# ATmega1609 register map
Vendor: Atmel; File version: 1.0
CPU: other r0p0, little endian, no MPU, no FPU, 4 interrupt priority bits
Registers are 8-bit, read-write, reset 0x0 unless marked. A register's access mark holds for its fields unless they carry their own. Offsets are from the block's base; [hi:lo] are bit positions; {n}, {i} and the like mark numbered series.

## PORTA — I/O Ports
Base 0x00000400
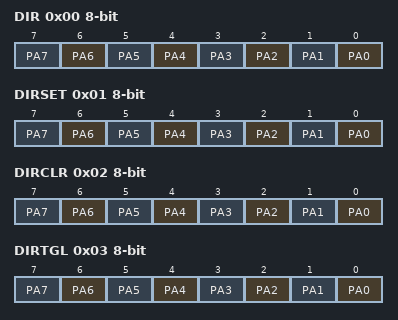
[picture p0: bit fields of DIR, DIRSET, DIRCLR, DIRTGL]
0x00 DIR — Data Direction
  [n] PA{n} (n=0..7) — Pin A{n}
0x01 DIRSET — Data Direction Set
  [n] PA{n} (n=0..7) — Pin A{n}
0x02 DIRCLR — Data Direction Clear
  [n] PA{n} (n=0..7) — Pin A{n}
0x03 DIRTGL — Data Direction Toggle
  [n] PA{n} (n=0..7) — Pin A{n}
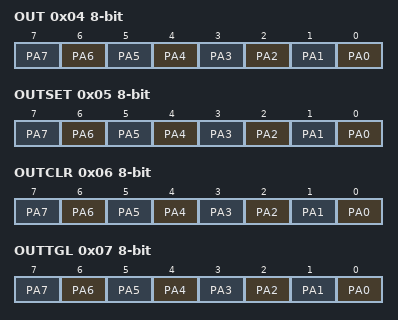
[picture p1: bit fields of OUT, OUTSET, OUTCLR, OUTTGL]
0x04 OUT — Output Value
  [n] PA{n} (n=0..7) — Pin A{n}
0x05 OUTSET — Output Value Set
  [n] PA{n} (n=0..7) — Pin A{n}
0x06 OUTCLR — Output Value Clear
  [n] PA{n} (n=0..7) — Pin A{n}
0x07 OUTTGL — Output Value Toggle
  [n] PA{n} (n=0..7) — Pin A{n}
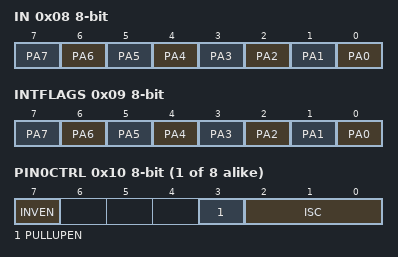
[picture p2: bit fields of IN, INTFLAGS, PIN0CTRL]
0x08 IN — Input Value
  [n] PA{n} (n=0..7) — Pin A{n}
0x09 INTFLAGS — Interrupt Flags
  [n] PA{n} (n=0..7) — Pin A{n}
0x0A PORTCTRL — Port Control
  [0] SRL — Slew Rate Limit Enable
{0x10+i} PIN{i}CTRL (i=0..7) — Pin {i} Control
  [7] INVEN — Inverted I/O Enable
  [3] PULLUPEN — Pullup enable
  [2:0] ISC — Input/Sense Configuration
    0=INTDISABLE (Interrupt disabled but input buffer enabled); 1=BOTHEDGES (Sense Both Edges); 2=RISING (Sense Rising Edge); 3=FALLING (Sense Falling Edge); 4=INPUT_DISABLE (Digital Input Buffer disabled); 5=LEVEL (Sense low Level)

## PORTB — I/O Ports
Base 0x00000420
Registers as PORTA; these are added or differ:
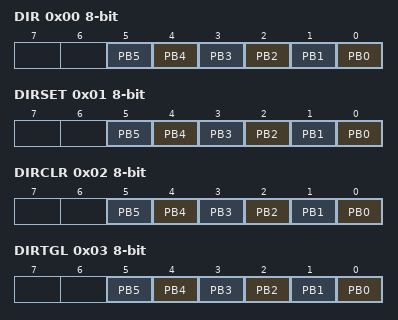
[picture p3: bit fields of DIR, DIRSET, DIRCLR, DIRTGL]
0x00 DIR — Data Direction
  [n] PB{n} (n=0..5) — Pin B{n}
0x01 DIRSET — Data Direction Set
  [n] PB{n} (n=0..5) — Pin B{n}
0x02 DIRCLR — Data Direction Clear
  [n] PB{n} (n=0..5) — Pin B{n}
0x03 DIRTGL — Data Direction Toggle
  [n] PB{n} (n=0..5) — Pin B{n}
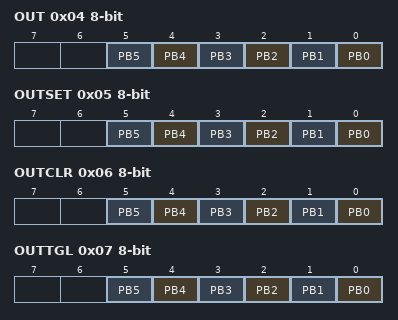
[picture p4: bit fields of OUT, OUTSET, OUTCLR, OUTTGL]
0x04 OUT — Output Value
  [n] PB{n} (n=0..5) — Pin B{n}
0x05 OUTSET — Output Value Set
  [n] PB{n} (n=0..5) — Pin B{n}
0x06 OUTCLR — Output Value Clear
  [n] PB{n} (n=0..5) — Pin B{n}
0x07 OUTTGL — Output Value Toggle
  [n] PB{n} (n=0..5) — Pin B{n}
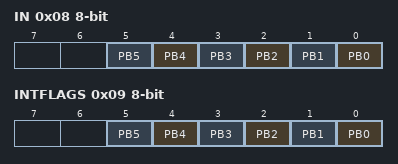
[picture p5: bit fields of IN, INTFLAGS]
0x08 IN — Input Value
  [n] PB{n} (n=0..5) — Pin B{n}
0x09 INTFLAGS — Interrupt Flags
  [n] PB{n} (n=0..5) — Pin B{n}

## PORTC — I/O Ports
Base 0x00000440
Registers as PORTA, without PORTCTRL; these are added or differ:
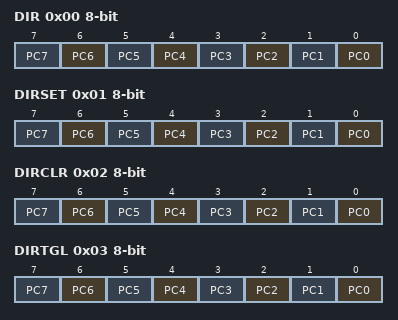
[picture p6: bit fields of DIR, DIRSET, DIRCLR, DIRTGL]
0x00 DIR — Data Direction
  [n] PC{n} (n=0..7) — Pin C{n}
0x01 DIRSET — Data Direction Set
  [n] PC{n} (n=0..7) — Pin C{n}
0x02 DIRCLR — Data Direction Clear
  [n] PC{n} (n=0..7) — Pin C{n}
0x03 DIRTGL — Data Direction Toggle
  [n] PC{n} (n=0..7) — Pin C{n}
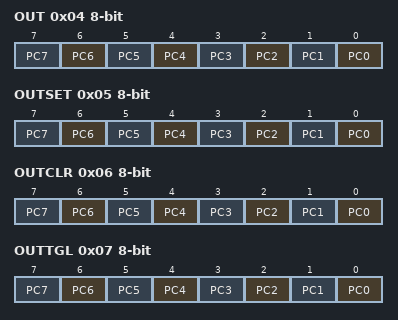
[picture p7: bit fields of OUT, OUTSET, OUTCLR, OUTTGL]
0x04 OUT — Output Value
  [n] PC{n} (n=0..7) — Pin C{n}
0x05 OUTSET — Output Value Set
  [n] PC{n} (n=0..7) — Pin C{n}
0x06 OUTCLR — Output Value Clear
  [n] PC{n} (n=0..7) — Pin C{n}
0x07 OUTTGL — Output Value Toggle
  [n] PC{n} (n=0..7) — Pin C{n}
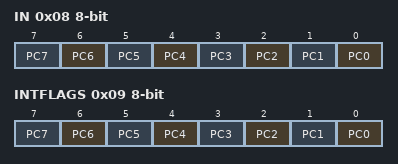
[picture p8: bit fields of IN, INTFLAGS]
0x08 IN — Input Value
  [n] PC{n} (n=0..7) — Pin C{n}
0x09 INTFLAGS — Interrupt Flags
  [n] PC{n} (n=0..7) — Pin C{n}
0x0A PORTCTRL — Port Control
  [0] SRL — Slew Rate Limit Enable

## PORTD — I/O Ports
Base 0x00000460
Registers as PORTA; these are added or differ:
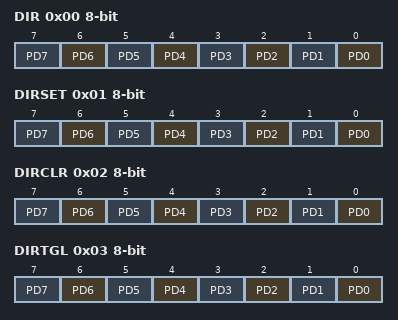
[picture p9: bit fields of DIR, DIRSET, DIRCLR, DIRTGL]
0x00 DIR — Data Direction
  [n] PD{n} (n=0..7) — Pin D{n}
0x01 DIRSET — Data Direction Set
  [n] PD{n} (n=0..7) — Pin D{n}
0x02 DIRCLR — Data Direction Clear
  [n] PD{n} (n=0..7) — Pin D{n}
0x03 DIRTGL — Data Direction Toggle
  [n] PD{n} (n=0..7) — Pin D{n}
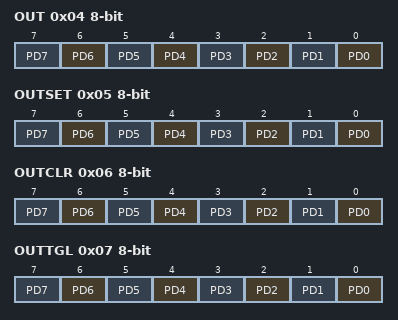
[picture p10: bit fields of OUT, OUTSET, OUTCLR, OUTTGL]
0x04 OUT — Output Value
  [n] PD{n} (n=0..7) — Pin D{n}
0x05 OUTSET — Output Value Set
  [n] PD{n} (n=0..7) — Pin D{n}
0x06 OUTCLR — Output Value Clear
  [n] PD{n} (n=0..7) — Pin D{n}
0x07 OUTTGL — Output Value Toggle
  [n] PD{n} (n=0..7) — Pin D{n}
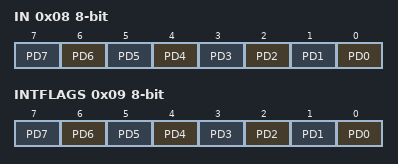
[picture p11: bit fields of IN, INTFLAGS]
0x08 IN — Input Value
  [n] PD{n} (n=0..7) — Pin D{n}
0x09 INTFLAGS — Interrupt Flags
  [n] PD{n} (n=0..7) — Pin D{n}

## PORTE — I/O Ports
Base 0x00000480
Registers as PORTA; these are added or differ:
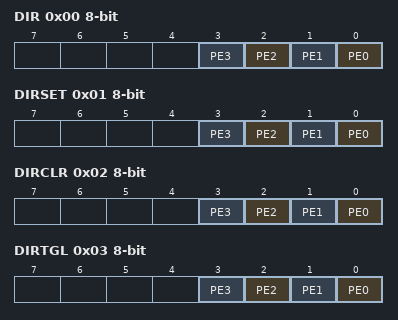
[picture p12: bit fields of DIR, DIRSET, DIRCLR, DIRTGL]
0x00 DIR — Data Direction
  [n] PE{n} (n=0..3) — Pin E{n}
0x01 DIRSET — Data Direction Set
  [n] PE{n} (n=0..3) — Pin E{n}
0x02 DIRCLR — Data Direction Clear
  [n] PE{n} (n=0..3) — Pin E{n}
0x03 DIRTGL — Data Direction Toggle
  [n] PE{n} (n=0..3) — Pin E{n}
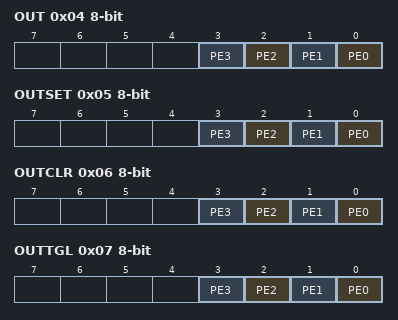
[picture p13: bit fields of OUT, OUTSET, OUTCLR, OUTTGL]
0x04 OUT — Output Value
  [n] PE{n} (n=0..3) — Pin E{n}
0x05 OUTSET — Output Value Set
  [n] PE{n} (n=0..3) — Pin E{n}
0x06 OUTCLR — Output Value Clear
  [n] PE{n} (n=0..3) — Pin E{n}
0x07 OUTTGL — Output Value Toggle
  [n] PE{n} (n=0..3) — Pin E{n}
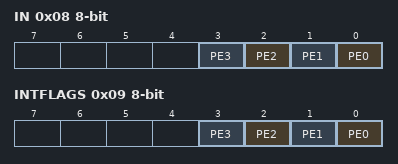
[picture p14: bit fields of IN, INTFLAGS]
0x08 IN — Input Value
  [n] PE{n} (n=0..3) — Pin E{n}
0x09 INTFLAGS — Interrupt Flags
  [n] PE{n} (n=0..3) — Pin E{n}

## PORTF — I/O Ports
Base 0x000004A0
Registers as PORTA; these are added or differ:
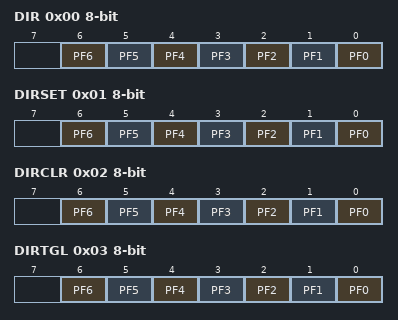
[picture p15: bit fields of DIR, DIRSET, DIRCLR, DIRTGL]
0x00 DIR — Data Direction
  [n] PF{n} (n=0..6) — Pin F{n}
0x01 DIRSET — Data Direction Set
  [n] PF{n} (n=0..6) — Pin F{n}
0x02 DIRCLR — Data Direction Clear
  [n] PF{n} (n=0..6) — Pin F{n}
0x03 DIRTGL — Data Direction Toggle
  [n] PF{n} (n=0..6) — Pin F{n}
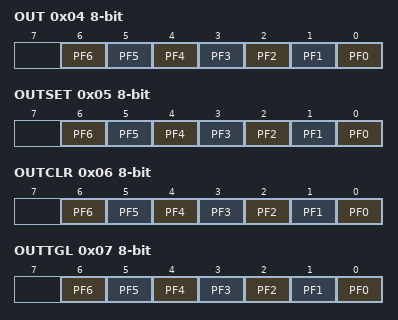
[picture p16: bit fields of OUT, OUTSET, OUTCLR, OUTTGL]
0x04 OUT — Output Value
  [n] PF{n} (n=0..6) — Pin F{n}
0x05 OUTSET — Output Value Set
  [n] PF{n} (n=0..6) — Pin F{n}
0x06 OUTCLR — Output Value Clear
  [n] PF{n} (n=0..6) — Pin F{n}
0x07 OUTTGL — Output Value Toggle
  [n] PF{n} (n=0..6) — Pin F{n}
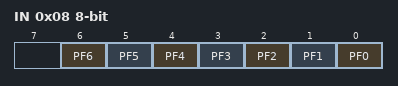
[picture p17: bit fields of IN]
0x08 IN — Input Value
  [n] PF{n} (n=0..6) — Pin F{n}
0x09 INTFLAGS — Interrupt Flags
  [n] PF{n} (n=0..6) — Pin F{n}
